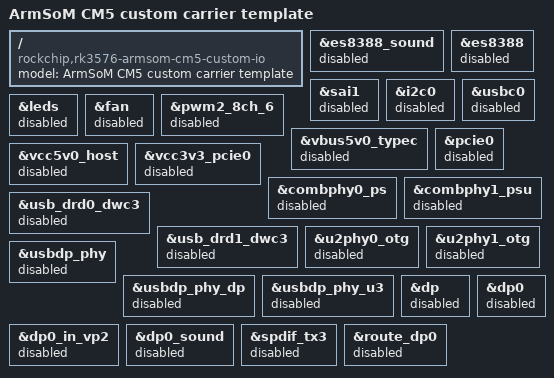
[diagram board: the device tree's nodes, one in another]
// SPDX-License-Identifier: (GPL-2.0+ OR MIT)
/*
 * Custom-carrier starting point, not an automatic carrier detector.
 * Review the inherited CM5-IO power topology and all external connections
 * before using it on a new PCB. Keep the official CM5-IO DTB for CM5-IO.
 * See Documentation/arm64/rockchip/cm5-carrier-overlays.rst.
 */
#include "rk3576-armsom-cm5-io.dts"

/ {
	model = "ArmSoM CM5 custom carrier template";
	compatible = "rockchip,rk3576-armsom-cm5-custom-io", "rockchip,rk3576";
};

&es8388_sound {
	status = "disabled";
};

&es8388 {
	status = "disabled";
};

&sai1 {
	status = "disabled";
};

&i2c0 {
	status = "disabled";
};

&usbc0 {
	status = "disabled";
};

&leds {
	status = "disabled";
};

&fan {
	status = "disabled";
};

&pwm2_8ch_6 {
	status = "disabled";
};

&vbus5v0_typec {
	status = "disabled";
};

&vcc5v0_host {
	status = "disabled";
};

&vcc3v3_pcie0 {
	status = "disabled";
};

&pcie0 {
	status = "disabled";
};

&combphy0_ps {
	status = "disabled";
};

&combphy1_psu {
	status = "disabled";
};

&usb_drd0_dwc3 {
	status = "disabled";
};

&usb_drd1_dwc3 {
	status = "disabled";
};

&u2phy0_otg {
	status = "disabled";
};

&u2phy1_otg {
	status = "disabled";
};

&usbdp_phy {
	status = "disabled";
};

&usbdp_phy_dp {
	status = "disabled";
};

&usbdp_phy_u3 {
	status = "disabled";
};

&dp {
	status = "disabled";
};

&dp0 {
	status = "disabled";
};

&dp0_in_vp2 {
	status = "disabled";
};

&dp0_sound {
	status = "disabled";
};

&spdif_tx3 {
	status = "disabled";
};

&route_dp0 {
	status = "disabled";
};
